# STM32H523 register map
File version: 1.2
CPU: CM33 r0p0, little endian, MPU, FPU, 4 interrupt priority bits
Registers are 32-bit, read-write, reset 0x0 unless marked. A register's access mark holds for its fields unless they carry their own. Offsets are from the block's base; [hi:lo] are bit positions; {n}, {i} and the like mark numbered series; 'fields as' and 'values as' point back to an identical list.

## TIM2 — TIM2 address block description
Base 0x40000000
Same registers: TIM2_S 0x50000000
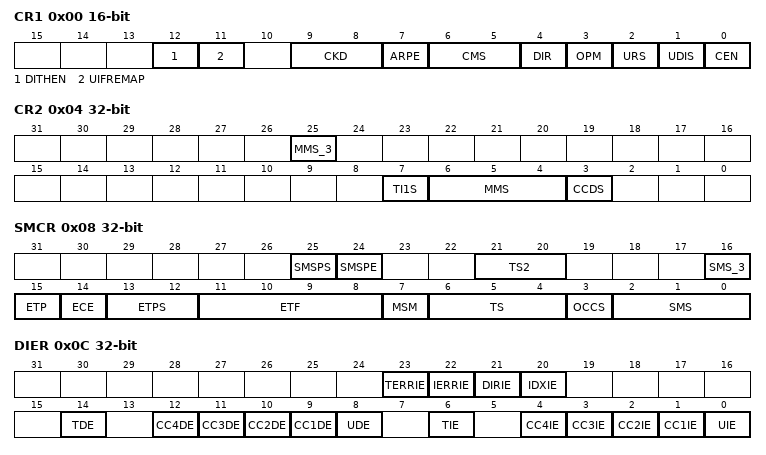
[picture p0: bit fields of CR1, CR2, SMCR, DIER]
0x00 CR1 16-bit — TIM2 control register 1
  [12] DITHEN — Dithering Enable
    0=Disabled (Dithering disabled); 1=Enabled (Dithering enabled)
  [11] UIFREMAP — UIF status bit remapping
    0=Disabled (No remapping. UIF status bit is not copied to TIMx_CNT register bit 31); 1=Enabled (Remapping enabled. UIF status bit is copied to TIMx_CNT register bit 31)
  [9:8] CKD — Clock division
    0=Div1 (t_DTS = t_CK_INT); 1=Div2 (t_DTS = 2 × t_CK_INT); 2=Div4 (t_DTS = 4 × t_CK_INT)
  [7] ARPE — Auto-reload preload enable
    0=Disabled (TIMx_APRR register is not buffered); 1=Enabled (TIMx_APRR register is buffered)
  [6:5] CMS — Center-aligned mode selection
    0=EdgeAligned (The counter counts up or down depending on the direction bit); 1=CenterAligned1 (The counter counts up and down alternatively. Output compare interrupt flags are set only when the counter is counting down.); 2=CenterAligned2 (The counter counts up and down alternatively. Output compare interrupt flags are set only when the counter is counting up.); 3=CenterAligned3 (The counter counts up and down alternatively. Output compare interrupt flags are set both when the counter is counting up or down.)
  [4] DIR — Direction
    0=Up (Counter used as upcounter); 1=Down (Counter used as downcounter)
  [3] OPM — One-pulse mode
    0=Disabled (Counter is not stopped at update event); 1=Enabled (Counter stops counting at the next update event (clearing the CEN bit))
  [2] URS — Update request source
    0=AnyEvent (Any of counter overflow/underflow, setting UG, or update through slave mode, generates an update interrupt or DMA request); 1=CounterOnly (Only counter overflow/underflow generates an update interrupt or DMA request)
  [1] UDIS — Update disable
    0=Enabled (Update event enabled); 1=Disabled (Update event disabled)
  [0] CEN — Counter enable
    0=Disabled (Counter disabled); 1=Enabled (Counter enabled)
0x04 CR2 — TIM2 control register 2
  [25] MMS_3
  [7] TI1S — tim_ti1 selection
    0=Normal (The TIMx_CH1 pin is connected to TI1 input); 1=XOR (The TIMx_CH1, CH2, CH3 pins are connected to TI1 input)
  [6:4] MMS — MMS[2:0]: Master mode selection
  [3] CCDS — Capture/compare DMA selection
    0=OnCompare (CCx DMA request sent when CCx event occurs); 1=OnUpdate (CCx DMA request sent when update event occurs)
0x08 SMCR — TIM2 slave mode control register
  [25] SMSPS — SMS preload source
    0=Update (SMSM[3:0] is preloaded from Update event); 1=Index (SMSM[3:0] is preloaded from Index event)
  [24] SMSPE — SMS preload enable
    0=NotPreloaded (SMSM[3:0] is not preloaded); 1=PreloadEnabled (SMSM[3:0] is preload is enabled)
  [21:20] TS2 — Trigger selection This bit-field selects the trigger input to be used to synchronize the counter. Others: Reserved See for product specific implementation details. Note: These bits must be changed only when they are not used (e.g. when SMS=000) to avoid wrong edge detections at the transition.
  [16] SMS_3 — Slave mode selection When external signals are selected the active edge of the trigger signal (tim_trgi) is linked to the polarity selected on the external input (see Input Control register and Control Register description. Note: The gated mode must not be used if tim_ti1f_ed is selected as the trigger input (TS=00100). Indeed, tim_ti1f_ed outputs 1 pulse for each transition on tim_ti1f, whereas the gated mode checks the level of the trigger signal. Note: The clock of the slave peripherals (timer, ADC, ...) receiving the tim_trgo signal must be enabled prior to receive events from the master timer, and the clock frequency (prescaler) must not be changed on-the-fly while triggers are received from the master timer.
  [15] ETP — External trigger polarity
    0=NotInverted (ETR is noninverted, active at high level or rising edge); 1=Inverted (ETR is inverted, active at low level or falling edge)
  [14] ECE — External clock enable
    0=Disabled (External clock mode 2 disabled); 1=Enabled (External clock mode 2 enabled. The counter is clocked by any active edge on the ETRF signal.)
  [13:12] ETPS — External trigger prescaler
    0=Div1 (Prescaler OFF); 1=Div2 (ETRP frequency divided by 2); 2=Div4 (ETRP frequency divided by 4); 3=Div8 (ETRP frequency divided by 8)
  [11:8] ETF — External trigger filter
    0=No filter, sampling is done at fDTS; 1=FCK_INT_N2 (fSAMPLING=fCK_INT, N=2); 2=FCK_INT_N4 (fSAMPLING=fCK_INT, N=4); 3=FCK_INT_N8 (fSAMPLING=fCK_INT, N=8); 4=FDTS_Div2_N6 (fSAMPLING=fDTS/2, N=6); 5=FDTS_Div2_N8 (fSAMPLING=fDTS/2, N=8); 6=FDTS_Div4_N6 (fSAMPLING=fDTS/4, N=6); 7=FDTS_Div4_N8 (fSAMPLING=fDTS/4, N=8); 8=FDTS_Div8_N6 (fSAMPLING=fDTS/8, N=6); 9=FDTS_Div8_N8 (fSAMPLING=fDTS/8, N=8); 10=FDTS_Div16_N5 (fSAMPLING=fDTS/16, N=5); 11=FDTS_Div16_N6 (fSAMPLING=fDTS/16, N=6); 12=FDTS_Div16_N8 (fSAMPLING=fDTS/16, N=8); 13=FDTS_Div32_N5 (fSAMPLING=fDTS/32, N=5); 14=FDTS_Div32_N6 (fSAMPLING=fDTS/32, N=6); 15=FDTS_Div32_N8 (fSAMPLING=fDTS/32, N=8)
  [7] MSM — Master/Slave mode
    0=NoSync (No action); 1=Sync (The effect of an event on the trigger input (TRGI) is delayed to allow a perfect synchronization between the current timer and its slaves (through TRGO). It is useful if we want to synchronize several timers on a single external event.)
  [6:4] TS — TS[2:0]: Trigger selection
  [3] OCCS — OCREF clear selection
  [2:0] SMS — SMS[2:0]: Slave mode selection
0x0C DIER — TIM2 DMA/Interrupt enable register
  [23] TERRIE — Transition error interrupt enable
    0=Disabled (Transition error interrupt disabled); 1=Enabled (Transition error interrupt enabled)
  [22] IERRIE — Index error interrupt enable
    0=Disabled (Index error interrupt disabled); 1=Enabled (Index error interrupt enabled)
  [21] DIRIE — Direction change interrupt enable
    0=Disabled (Direction change interrupt disabled); 1=Enabled (Direction change interrupt enabled)
  [20] IDXIE — Index interrupt enable
    0=Disabled (Index change interrupt disabled); 1=Enabled (Index change interrupt enabled)
  [14] TDE — Trigger DMA request enable
    0=Disabled (Trigger DMA request disabled); 1=Enabled (Trigger DMA request enabled)
  [n+8] CC{n}DE (n=1..4) — Capture/Compare {n} DMA request enable
    0=Disabled (CCx DMA request disabled); 1=Enabled (CCx DMA request enabled)
  [8] UDE — Update DMA request enable
    0=Disabled (Update DMA request disabled); 1=Enabled (Update DMA request enabled)
  [6] TIE — Trigger interrupt enable
    0=Disabled (Trigger interrupt disabled); 1=Enabled (Trigger interrupt enabled)
  [n] CC{n}IE (n=1..4) — Capture/Compare {n} interrupt enable
    0=Disabled (CCx interrupt disabled); 1=Enabled (CCx interrupt enabled)
  [0] UIE — Update interrupt enable
    0=Disabled (Update interrupt disabled); 1=Enabled (Update interrupt enabled)
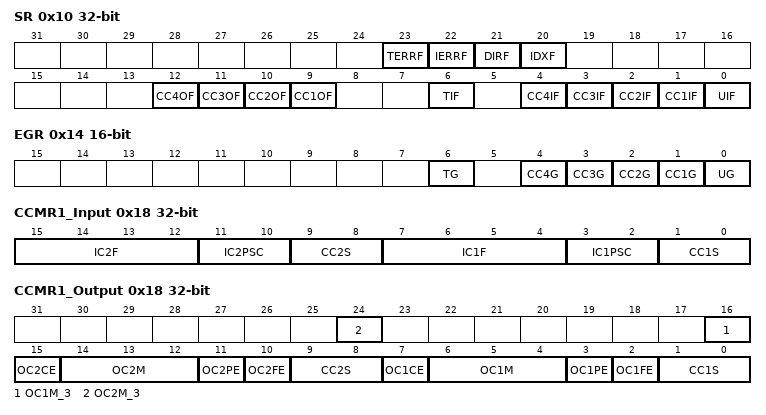
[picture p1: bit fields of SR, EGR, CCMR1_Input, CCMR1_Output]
0x10 SR — TIM2 status register
  [23] TERRF write-0-clears — Transition error interrupt flag
    on read: 0=NoTrigger (No encoder transition error has been detected); 1=Trigger (An encoder transition error has been detected) | on write: 0=Clear flag
  [22] IERRF write-0-clears — Index error interrupt flag
    on read: 0=NoTrigger (No index error has been detected); 1=Trigger (An index erorr has been detected) | on write: 0=Clear flag
  [21] DIRF write-0-clears — Direction change interrupt flag
    on read: 0=NoTrigger (No direction change has been detected); 1=Trigger (A direction change has been detected) | on write: 0=Clear flag
  [20] IDXF write-0-clears — Index interrupt flag
    on read: 0=NoTrigger (No index event occurred); 1=Trigger (An index event has occurred) | on write: 0=Clear flag
  [n+8] CC{n}OF (n=1..4) write-0-clears — Capture/Compare {n} overcapture flag
    on read: 0=No overcapture has been detected; 1=Overcapture (The counter value has been captured in TIMx_CCRx register while CCxIF flag was already set) | on write: 0=Clear flag
  [6] TIF write-0-clears — Trigger interrupt flag
    on read: 0=No trigger event occurred; 1=Trigger interrupt pending | on write: 0=Clear flag
  [n] CC{n}IF (n=1..4) write-0-clears — Capture/compare {n} interrupt flag
    on read: 0=NoMatch (No campture/compare has been detected); 1=Match (If CC1 is an output: The content of the counter TIMx_CNT matches the content of the TIMx_CCR1 register. If CC1 is an input: The counter value has been captured in TIMx_CCR1 register.) | on write: 0=Clear flag
  [0] UIF write-0-clears — Update interrupt flag
    on read: 0=NoUpdateOccurred; 1=UpdatePending (Update interrupt pending) | on write: 0=Clear flag
0x14 EGR 16-bit wo — TIM2 event generation register
  [6] TG — Trigger generation
    1=Trigger (The TIF flag is set in TIMx_SR register. Related interrupt or DMA transfer can occur if enabled.)
  [n] CC{n}G (n=1..4) — Capture/compare {n} generation
    1=Trigger (If CC1 is an output: CC1IF flag is set, Corresponding interrupt or DMA request is sent if enabled. If CC1 is an input: The current value of the counter is captured in TIMx_CCR1 register.)
  [0] UG — Update generation
    1=Update (Re-initializes the timer counter and generates an update of the registers.)
0x18 CCMR1_Input — TIM2 capture/compare mode register 1
  [9:8] CC2S — Capture/compare 2 selection
    1=TI2 (CC2 channel is configured as input, IC2 is mapped on TI2); 2=TI1 (CC2 channel is configured as input, IC2 is mapped on TI1); 3=TRC (CC2 channel is configured as input, IC2 is mapped on TRC)
  [8n-1:8n-4] IC{n}F (n=1..2) — Input capture {n} filter
    values as SMCR.ETF
  [8n-5:8n-6] IC{n}PSC (n=1..2) — Input capture {n} prescaler
    0=No prescaler, capture is done each time an edge is detected on the capture input; 1=TwoEvents (Capture is done once every 2 events); 2=FourEvents (Capture is done once every 4 events); 3=EightEvents (Capture is done once every 8 events)
  [1:0] CC1S — Capture/Compare 1 selection
    1=TI1 (CC1 channel is configured as input, IC1 is mapped on TI1); 2=TI2 (CC1 channel is configured as input, IC1 is mapped on TI2); 3=TRC (CC1 channel is configured as input, IC1 is mapped on TRC)
0x18 CCMR1_Output (alternate view of CCMR1_Input) — TIM2 capture/compare mode register 1
  [8n+8] OC{n}M_3 (n=1..2) — Output compare {n} mode, bit 3
    0=Normal output compare mode (modes 0-7); 1=Extended output compare mode (modes 7-15)
  [8n-1] OC{n}CE (n=1..2) — Output compare {n} clear enable
    0=Disabled (OCxRef is not affected by the ocref_clr_int signal); 1=Enabled (OCxRef is cleared as soon as a High level is detected on ocref_clr_int signal)
  [8n-2:8n-4] OC{n}M (n=1..2) — Output compare {n} mode
    0=Frozen (The comparison between the output compare register TIMx_CCRy and the counter TIMx_CNT has no effect on the outputs / OpmMode1: Retriggerable OPM mode 1 - In up-counting mode, the channel is active until a trigger event is detected (on TRGI signal). In down-counting mode, the channel is inactive); 1=ActiveOnMatch (Set channel to active level on match. OCyREF signal is forced high when the counter matches the capture/compare register / OpmMode2: Inversely to OpmMode1); 2=InactiveOnMatch (Set channel to inactive level on match. OCyREF signal is forced low when the counter matches the capture/compare register / Reserved); 3=Toggle (OCyREF toggles when TIMx_CNT=TIMx_CCRy / Reserved); 4=ForceInactive (OCyREF is forced low / CombinedPwmMode1: OCyREF has the same behavior as in PWM mode 1. OCyREFC is the logical OR between OC1REF and OC2REF); 5=ForceActive (OCyREF is forced high / CombinedPwmMode2: OCyREF has the same behavior as in PWM mode 2. OCyREFC is the logical AND between OC1REF and OC2REF); 6=PwmMode1 (In upcounting, channel is active as long as TIMx_CNT<TIMx_CCRy else inactive. In downcounting, channel is inactive as long as TIMx_CNT>TIMx_CCRy else active / AsymmetricPwmMode1: OCyREF has the same behavior as in PWM mode 1. OCyREFC outputs OC1REF when the counter is counting up, OC2REF when it is counting down); 7=PwmMode2 (Inversely to PwmMode1 / AsymmetricPwmMode2: Inversely to AsymmetricPwmMode1)
  [8n-5] OC{n}PE (n=1..2) — Output compare {n} preload enable
    0=Disabled (Preload register on CCRx disabled. New values written to CCRx are taken into account immediately); 1=Enabled (Preload register on CCRx enabled. Preload value is loaded into active register on each update event)
  [8n-6] OC{n}FE (n=1..2) — Output compare {n} fast enable
    0=Disabled (Fast output disabled); 1=Enabled (Fast output enabled)
  [8n-7:8n-8] CC{n}S (n=1..2) — Capture/Compare {n} selection
    0=Output (CCx channel is configured as output)
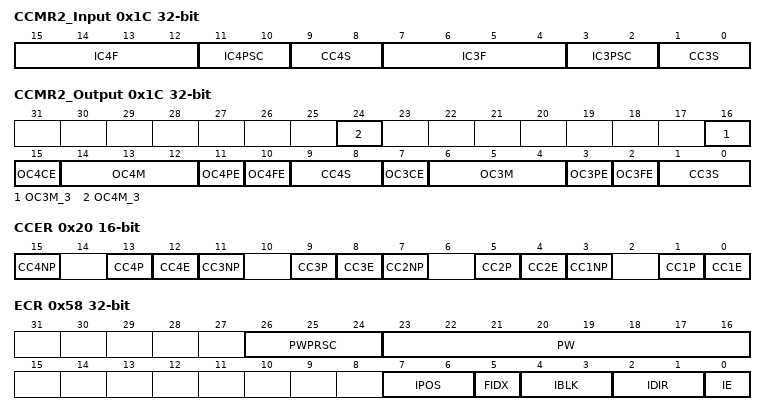
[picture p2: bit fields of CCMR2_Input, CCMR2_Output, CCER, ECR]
0x1C CCMR2_Input — TIM2 capture/compare mode register 2
  [9:8] CC4S — Capture/Compare 4 selection
    1=TI4 (CC4 channel is configured as input, IC4 is mapped on TI4); 2=TI3 (CC4 channel is configured as input, IC4 is mapped on TI3); 3=TRC (CC4 channel is configured as input, IC4 is mapped on TRC)
  [8n-17:8n-20] IC{n}F (n=3..4) — Input capture {n} filter
    values as SMCR.ETF
  [8n-21:8n-22] IC{n}PSC (n=3..4) — Input capture {n} prescaler
    values as CCMR1_Input.IC1PSC
  [1:0] CC3S — Capture/Compare 3 selection
    1=TI3 (CC3 channel is configured as input, IC3 is mapped on TI3); 2=TI4 (CC3 channel is configured as input, IC3 is mapped on TI4); 3=TRC (CC3 channel is configured as input, IC3 is mapped on TRC)
0x1C CCMR2_Output (alternate view of CCMR2_Input) — TIM2 capture/compare mode register 2
  [8n-8] OC{n}M_3 (n=3..4) — Output compare {n} mode, bit 3
    values as CCMR1_Output.OC1M_3
  [8n-17] OC{n}CE (n=3..4) — Output compare {n} clear enable
    values as CCMR1_Output.OC1CE
  [8n-18:8n-20] OC{n}M (n=3..4) — Output compare {n} mode
    values as CCMR1_Output.OC1M
  [8n-21] OC{n}PE (n=3..4) — Output compare {n} preload enable
    values as CCMR1_Output.OC1PE
  [8n-22] OC{n}FE (n=3..4) — Output compare {n} fast enable
    values as CCMR1_Output.OC1FE
  [8n-23:8n-24] CC{n}S (n=3..4) — Capture/Compare {n} selection
    0=Output (CCx channel is configured as output)
0x20 CCER 16-bit — TIM2 capture/compare enable register
  [4n-1] CC{n}NP (n=1..4) — Capture/Compare {n} output Polarity
  [4n-3] CC{n}P (n=1..4) — Capture/Compare {n} output Polarity
    0=RisingEdge (Noninverted/rising edge); 1=FallingEdge (Inverted/falling edge)
  [4n-4] CC{n}E (n=1..4) — Capture/Compare {n} output enable
    0=Disabled (Capture disabled); 1=Enabled (Capture enabled)
0x24 CNT — TIM2 counter
  [31] UIFCPY_CNT — Value depends on IUFREMAP in TIMx_CR1.
  [31] UIFCPY ro — Read-only copy of the UIF bit of the TIMx_ISR register
    0=NoUpdateOccurred; 1=UpdatePending (Update interrupt pending)
  [31:0] CNT — Non-dithering mode (DITHEN = 0) The register holds the counter value. Dithering mode (DITHEN = 1) The register holds the non-dithered part. The fractional part is not available.
0x28 PSC 16-bit — TIM2 prescaler
  [15:0] PSC — Prescaler value
0x2C ARR reset 0xFFFFFFFF — TIM2 auto-reload register
  [31:0] ARR — Auto-reload value
{0x30+4i} CCR{i} (i=1..4) — capture/compare register
  [31:0] CCR — Capture/Compare value
0x58 ECR — TIM2 timer encoder control register
  [26:24] PWPRSC — Pulse width prescaler
  [23:16] PW — Pulse width
  [7:6] IPOS — Index positioning
  [5] FIDX — First index
  [4:3] IBLK — Index blanking
  [2:1] IDIR — Index direction
  [0] IE — Index enable
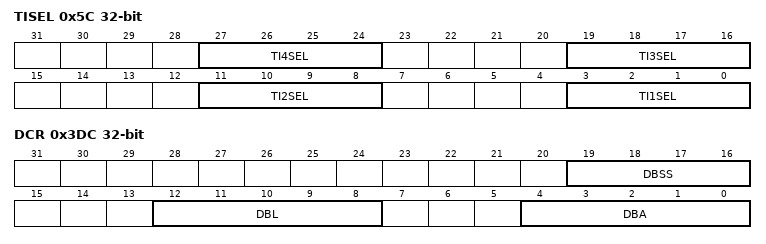
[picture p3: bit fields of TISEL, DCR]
0x5C TISEL — TIM2 timer input selection register
  [all] fields
    0=Selected (TIM1_CHx input selected)
  [8n-5:8n-8] TI{n}SEL (n=1..4) — Selects tim_ti{n}[15:0] input
0x60 AF1 — TIM2 alternate function register 1
  [17:14] ETRSEL — etr_in source selection
    0=Legacy (ETR legacy mode); 1=COMP1 (COMP1 output); 2=COMP2 (COMP2 output)
0x64 AF2 — TIM2 alternate function register 2
  [18:16] OCRSEL — ocref_clr source selection
0x3DC DCR — TIM2 DMA control register
  [19:16] DBSS range 0..7 — DMA burst source selection
  [12:8] DBL range 0..18 — DMA burst length
  [4:0] DBA — DMA base address
0x3E0 DMAR — TIM2 DMA address for full transfer
  [31:0] DMAB — DMA register for burst accesses

## TIM3 — TIM3 address block description
Base 0x40000400
Same registers: TIM3_S 0x50000400
Registers as TIM2 (with TIM2 read as TIM3); these are added or differ:
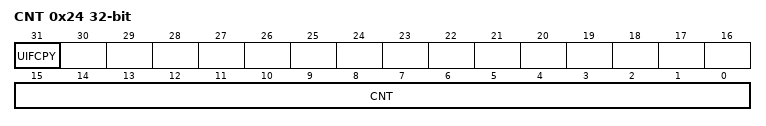
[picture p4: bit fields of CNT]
0x24 CNT — TIM3 counter
  [31] UIFCPY — Value depends on IUFREMAP in TIMx_CR1.
    on read: 0=NoUpdateOccurred; 1=UpdatePending (Update interrupt pending)
  [15:0] CNT — Counter value
0x2C ARR reset 0xFFFF — TIM3 auto-reload register
  [19:0] ARR — Low Auto-reload value
{0x30+4i} CCR{i} (i=1..4) — capture/compare register
  [19:0] CCR — Capture/Compare value

## TIM4 — TIM4 address block description
Base 0x40000800
Same registers: TIM4_S 0x50000800
Registers as TIM3 (with TIM3 read as TIM4).

## TIM5 — TIM5 address block description
Base 0x40000C00
Same registers: TIM5_S 0x50000C00
Registers as TIM2 (with TIM2 read as TIM5).
